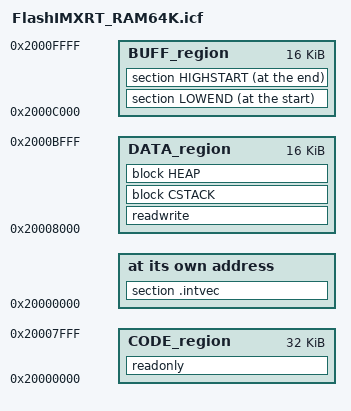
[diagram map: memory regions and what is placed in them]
/*###ICF### Section handled by ICF editor, don't touch! ****/
/*-Editor annotation file-*/
/* IcfEditorFile="$TOOLKIT_DIR$\config\ide\IcfEditor\cortex_v1_0.xml" */
/*-Specials-*/
define symbol __ICFEDIT_intvec_start__ = 0x20000000;
/*-Memory Regions-*/
define symbol __ICFEDIT_region_ROM_start__   = 0x20000000;
define symbol __ICFEDIT_region_ROM_end__     = 0x20007FFF;
define symbol __ICFEDIT_region_RAM_start__   = 0x20008000;
define symbol __ICFEDIT_region_RAM_end__     = 0x2000BFFF;
define symbol __ICFEDIT_region_RAM2_start__  = 0x2000C000;
define symbol __ICFEDIT_region_RAM2_end__    = 0x2000FFFF;
/*-Sizes-*/
define symbol __ICFEDIT_size_cstack__   = 0x1000;
define symbol __ICFEDIT_size_heap__     = 0x100;
/**** End of ICF editor section. ###ICF###*/

define memory mem with size = 4G;
define region CODE_region = mem:[from __ICFEDIT_region_ROM_start__ to __ICFEDIT_region_ROM_end__];
define region DATA_region = mem:[from __ICFEDIT_region_RAM_start__ to __ICFEDIT_region_RAM_end__];
define region BUFF_region = mem:[from __ICFEDIT_region_RAM2_start__   to __ICFEDIT_region_RAM2_end__];

define block CSTACK    with alignment = 8, size = __ICFEDIT_size_cstack__   { };
define block HEAP      with alignment = 8, size = __ICFEDIT_size_heap__     { };

do not initialize { zi };

place at address mem:__ICFEDIT_intvec_start__ { section .intvec };

place in CODE_region { readonly };
place in DATA_region { readwrite, block CSTACK, block HEAP };
place at start of BUFF_region {section LOWEND};
place at end of BUFF_region   {section HIGHSTART};
